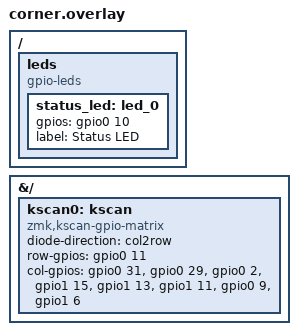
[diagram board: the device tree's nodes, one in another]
#include "corner.dtsi"

&{/} {

    kscan0: kscan {
        compatible = "zmk,kscan-gpio-matrix";

        diode-direction = "col2row";

        row-gpios = <
            &gpio0 11 GPIO_ACTIVE_HIGH
        >;

        col-gpios = <
            &gpio0 31 GPIO_ACTIVE_HIGH
            &gpio0 29 GPIO_ACTIVE_HIGH
            &gpio0 2 GPIO_ACTIVE_HIGH
            &gpio1 15 GPIO_ACTIVE_HIGH
            &gpio1 13 GPIO_ACTIVE_HIGH
            &gpio1 11 GPIO_ACTIVE_HIGH
            &gpio0 9 GPIO_ACTIVE_HIGH
            &gpio1 6 GPIO_ACTIVE_HIGH
        >;
    };
};
/ {
    leds {
        compatible = "gpio-leds";

        status_led: led_0 {
            gpios = <&gpio0 10 GPIO_ACTIVE_HIGH>;
            label = "Status LED";
        };
    };
};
